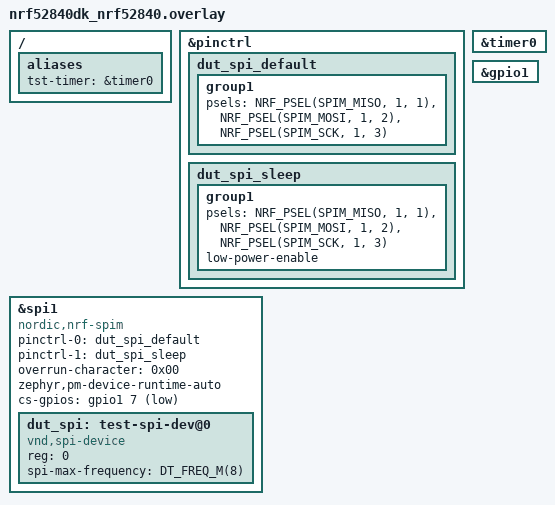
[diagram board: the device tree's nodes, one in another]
/*
 * Copyright (c) 2025 Nordic Semiconductor ASA
 *
 * SPDX-License-Identifier: LicenseRef-Nordic-5-Clause
 */

/* Required loopbacks:
 * P1.01 <-> P1.02
 */

/ {
	aliases {
		tst-timer = &timer0;
	};
};

&pinctrl {
	dut_spi_default: dut_spi_default {
		group1 {
			psels = <NRF_PSEL(SPIM_MISO, 1, 1)>,
				<NRF_PSEL(SPIM_MOSI, 1, 2)>,
				<NRF_PSEL(SPIM_SCK, 1, 3)>;
		};
	};

	dut_spi_sleep: dut_spi_sleep {
		group1 {
			psels = <NRF_PSEL(SPIM_MISO, 1, 1)>,
				<NRF_PSEL(SPIM_MOSI, 1, 2)>,
				<NRF_PSEL(SPIM_SCK, 1, 3)>;
			low-power-enable;
		};
	};
};

&spi1 {
	compatible = "nordic,nrf-spim";
	status = "okay";
	pinctrl-0 = <&dut_spi_default>;
	pinctrl-1 = <&dut_spi_sleep>;
	pinctrl-names = "default", "sleep";
	overrun-character = <0x00>;
	zephyr,pm-device-runtime-auto;
	cs-gpios = <&gpio1 7 GPIO_ACTIVE_LOW>;

	dut_spi: test-spi-dev@0 {
		compatible = "vnd,spi-device";
		reg = <0>;
		spi-max-frequency = <DT_FREQ_M(8)>;
	};
};

&timer0 {
	status = "okay";
};

&gpio1 {
	status = "okay";
};
